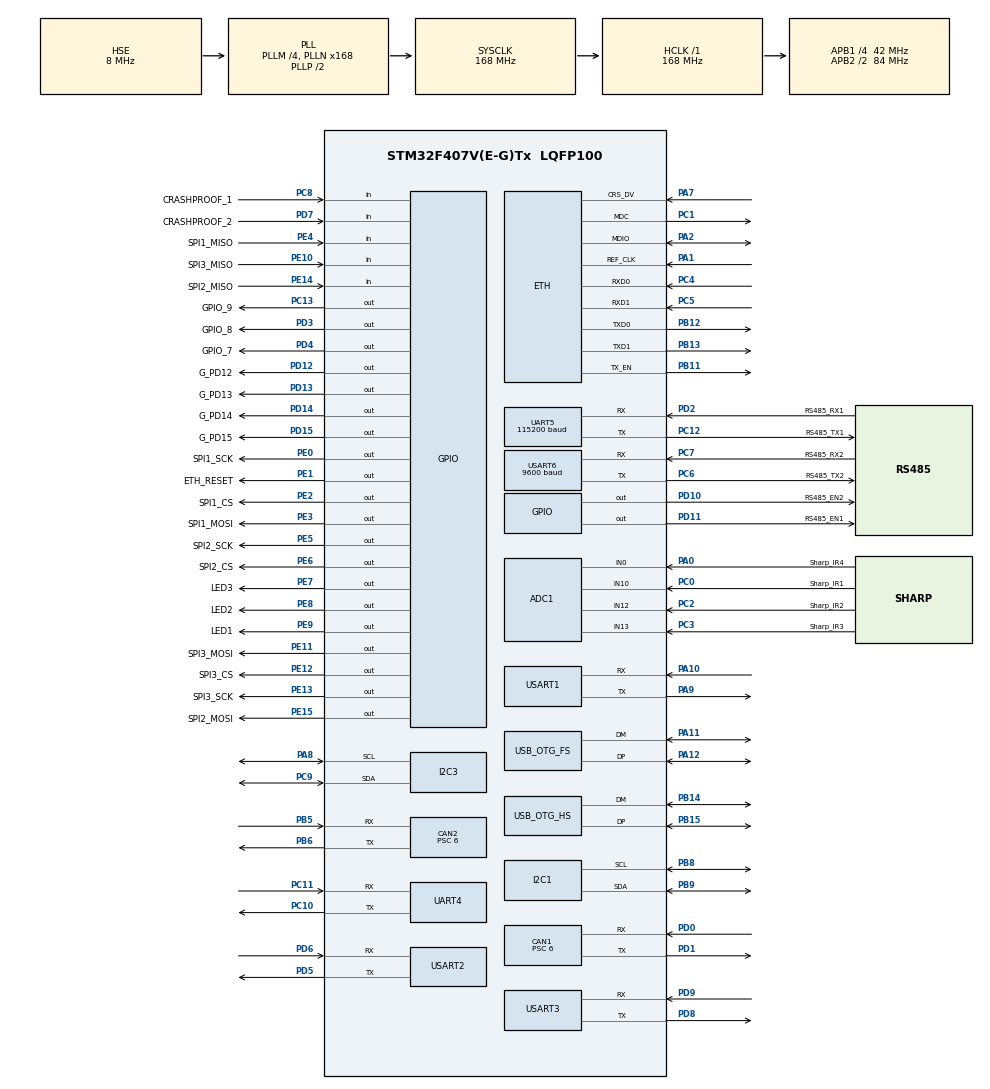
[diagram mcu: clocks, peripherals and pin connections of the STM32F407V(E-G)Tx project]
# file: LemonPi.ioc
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ADC1.Channel-0\#ChannelRegularConversion=ADC_CHANNEL_10
ADC1.Channel-1\#ChannelRegularConversion=ADC_CHANNEL_12
ADC1.Channel-2\#ChannelRegularConversion=ADC_CHANNEL_13
ADC1.Channel-3\#ChannelRegularConversion=ADC_CHANNEL_0
ADC1.ClockPrescaler=ADC_CLOCK_SYNC_PCLK_DIV8
ADC1.ContinuousConvMode=ENABLE
ADC1.DMAContinuousRequests=ENABLE
ADC1.InjNumberOfConversion=0
ADC1.NbrOfConversion=4
ADC1.NbrOfConversionFlag=1
ADC1.Rank-0\#ChannelRegularConversion=1
ADC1.Rank-1\#ChannelRegularConversion=2
ADC1.Rank-2\#ChannelRegularConversion=3
ADC1.Rank-3\#ChannelRegularConversion=4
ADC1.SamplingTime-0\#ChannelRegularConversion=ADC_SAMPLETIME_84CYCLES
ADC1.SamplingTime-1\#ChannelRegularConversion=ADC_SAMPLETIME_84CYCLES
ADC1.SamplingTime-2\#ChannelRegularConversion=ADC_SAMPLETIME_84CYCLES
ADC1.SamplingTime-3\#ChannelRegularConversion=ADC_SAMPLETIME_84CYCLES
ADC1.master=1
CAN1.BS1=CAN_BS1_5TQ
CAN1.CalculateBaudRate=1000000
CAN1.CalculateTimeBit=1000
CAN1.CalculateTimeQuantum=142.85714285714286
CAN1.Prescaler=6
CAN2.BS1=CAN_BS1_5TQ
CAN2.CalculateBaudRate=1000000
CAN2.CalculateTimeBit=1000
CAN2.CalculateTimeQuantum=142.85714285714286
CAN2.Prescaler=6
Dma.ADC1.2.Direction=DMA_PERIPH_TO_MEMORY
Dma.ADC1.2.FIFOMode=DMA_FIFOMODE_DISABLE
Dma.ADC1.2.Instance=DMA2_Stream0
Dma.ADC1.2.MemDataAlignment=DMA_MDATAALIGN_HALFWORD
Dma.ADC1.2.MemInc=DMA_MINC_ENABLE
Dma.ADC1.2.Mode=DMA_CIRCULAR
Dma.ADC1.2.PeriphDataAlignment=DMA_PDATAALIGN_HALFWORD
Dma.ADC1.2.PeriphInc=DMA_PINC_DISABLE
Dma.ADC1.2.Priority=DMA_PRIORITY_HIGH
Dma.Request0=USART1_RX
Dma.Request1=USART1_TX
Dma.Request2=ADC1
Dma.USART1_RX.0.Direction=DMA_PERIPH_TO_MEMORY
Dma.USART1_RX.0.FIFOMode=DMA_FIFOMODE_DISABLE
Dma.USART1_RX.0.Instance=DMA2_Stream2
Dma.USART1_RX.0.MemDataAlignment=DMA_MDATAALIGN_HALFWORD
Dma.USART1_RX.0.MemInc=DMA_MINC_ENABLE
Dma.USART1_RX.0.Mode=DMA_NORMAL
Dma.USART1_RX.0.PeriphDataAlignment=DMA_PDATAALIGN_HALFWORD
Dma.USART1_RX.0.PeriphInc=DMA_PINC_DISABLE
Dma.USART1_RX.0.Priority=DMA_PRIORITY_MEDIUM
Dma.USART1_TX.1.Direction=DMA_MEMORY_TO_PERIPH
Dma.USART1_TX.1.FIFOMode=DMA_FIFOMODE_DISABLE
Dma.USART1_TX.1.Instance=DMA2_Stream7
Dma.USART1_TX.1.MemDataAlignment=DMA_MDATAALIGN_WORD
Dma.USART1_TX.1.MemInc=DMA_MINC_ENABLE
Dma.USART1_TX.1.Mode=DMA_NORMAL
Dma.USART1_TX.1.PeriphDataAlignment=DMA_PDATAALIGN_WORD
Dma.USART1_TX.1.PeriphInc=DMA_PINC_DISABLE
Dma.USART1_TX.1.Priority=DMA_PRIORITY_LOW
ETH.MediaInterface=HAL_ETH_RMII_MODE
I2C1.OwnAddress=15
LWIP.BSP.number=1
LWIP.CHECKSUM_BY_HARDWARE=1
LWIP.DHCP_DEBUG=LWIP_DBG_ON
LWIP.GATEWAY_ADDRESS=192.168.001.001
LWIP.IP_ADDRESS=192.168.001.201
LWIP.IP_REASS_DEBUG=LWIP_DBG_ON
LWIP.LWIP_DHCP=0
LWIP.LWIP_DNS=0
LWIP.LWIP_NETIF_EXT_STATUS_CALLBACK=1
LWIP.LWIP_NETIF_STATUS_CALLBACK=1
LWIP.NETMASK_ADDRESS=255.255.255.000
LWIP.Version=v2.1.2_Cube
LWIP0.BSP.STBoard=false
LWIP0.BSP.api=BSP_COMPONENT_DRIVER
LWIP0.BSP.component=LAN8742
LWIP0.BSP.instance=LAN8742
LWIP0.BSP.name=Driver_PHY
LWIP0.BSP.semaphore=S_LAN8742
LWIP0.BSP.solution=LAN8742
Mcu.Family=STM32F4
Mcu.Name=STM32F407V(E-G)Tx
Mcu.Package=LQFP100
NVIC.CAN1_RX0_IRQn=true\:0\:0\:false\:false\:true\:true\:true\:true
NVIC.CAN2_RX0_IRQn=true\:0\:0\:false\:false\:true\:true\:true\:true
NVIC.DMA2_Stream0_IRQn=true\:0\:0\:false\:false\:true\:false\:true\:true
NVIC.DMA2_Stream2_IRQn=true\:0\:0\:false\:false\:true\:false\:true\:true
NVIC.DMA2_Stream7_IRQn=true\:0\:0\:false\:false\:true\:false\:true\:true
NVIC.OTG_FS_IRQn=true\:0\:0\:false\:false\:true\:false\:true\:true
NVIC.OTG_HS_IRQn=true\:0\:0\:false\:false\:true\:false\:true\:true
NVIC.PriorityGroup=NVIC_PRIORITYGROUP_4
NVIC.TIM2_IRQn=true\:3\:0\:true\:false\:true\:true\:true\:true
NVIC.UART4_IRQn=true\:0\:0\:false\:false\:true\:true\:true\:true
NVIC.UART5_IRQn=true\:0\:0\:false\:false\:true\:true\:true\:true
NVIC.USART1_IRQn=true\:0\:0\:false\:false\:true\:true\:true\:true
NVIC.USART2_IRQn=true\:2\:0\:true\:false\:true\:true\:true\:true
NVIC.USART3_IRQn=true\:0\:0\:false\:false\:true\:true\:true\:true
NVIC.USART6_IRQn=true\:0\:0\:true\:false\:true\:true\:true\:true
PA0-WKUP.GPIO_Label=Sharp_IR4
PA0-WKUP.Signal=ADCx_IN0
PA1.GPIO_Speed=GPIO_SPEED_FREQ_HIGH
PA1.Mode=RMII
PA1.Signal=ETH_REF_CLK
PA10.Mode=Asynchronous
PA10.Signal=USART1_RX
PA11.Mode=Device_Only
PA11.Signal=USB_OTG_FS_DM
PA12.Mode=Device_Only
PA12.Signal=USB_OTG_FS_DP
PA13.Mode=JTAG_5_pins
PA13.Signal=SYS_JTMS-SWDIO
PA14.Mode=JTAG_5_pins
PA14.Signal=SYS_JTCK-SWCLK
PA15.Mode=JTAG_5_pins
PA15.Signal=SYS_JTDI
PA2.GPIO_Speed=GPIO_SPEED_FREQ_HIGH
PA2.Mode=RMII
PA2.Signal=ETH_MDIO
PA7.GPIO_Speed=GPIO_SPEED_FREQ_HIGH
PA7.Mode=RMII
PA7.Signal=ETH_CRS_DV
PA8.GPIO_Pu=GPIO_PULLUP
PA8.Mode=I2C
PA8.Signal=I2C3_SCL
PA9.Mode=Asynchronous
PA9.Signal=USART1_TX
PB11.GPIO_Speed=GPIO_SPEED_FREQ_HIGH
PB11.Mode=RMII
PB11.Signal=ETH_TX_EN
PB12.GPIO_Speed=GPIO_SPEED_FREQ_HIGH
PB12.Mode=RMII
PB12.Signal=ETH_TXD0
PB13.GPIO_Speed=GPIO_SPEED_FREQ_HIGH
PB13.Mode=RMII
PB13.Signal=ETH_TXD1
PB14.Mode=Device_Only_FS
PB14.Signal=USB_OTG_HS_DM
PB15.Mode=Device_Only_FS
PB15.Signal=USB_OTG_HS_DP
PB2.Signal=EVENTOUT
PB3.Mode=JTAG_5_pins
PB3.Signal=SYS_JTDO-SWO
PB4.Mode=JTAG_5_pins
PB4.Signal=SYS_JTRST
PB5.Mode=CAN_Activate
PB5.Signal=CAN2_RX
PB6.Mode=CAN_Activate
PB6.Signal=CAN2_TX
PB8.GPIO_Pu=GPIO_PULLUP
PB8.Mode=I2C
PB8.Signal=I2C1_SCL
PB9.GPIO_Pu=GPIO_PULLUP
PB9.Mode=I2C
PB9.Signal=I2C1_SDA
PC0.GPIO_Label=Sharp_IR1
PC0.Signal=ADCx_IN10
PC1.GPIO_Speed=GPIO_SPEED_FREQ_HIGH
PC1.Mode=RMII
PC1.Signal=ETH_MDC
PC10.Mode=Asynchronous
PC10.Signal=UART4_TX
PC11.Mode=Asynchronous
PC11.Signal=UART4_RX
PC12.GPIO_Label=RS485_TX1
PC12.GPIO_Speed=GPIO_SPEED_FREQ_MEDIUM
PC12.Mode=Asynchronous
PC12.Signal=UART5_TX
PC13-ANTI_TAMP.GPIO_Label=GPIO_9
PC13-ANTI_TAMP.GPIO_ModeDefaultOutputPP=GPIO_MODE_OUTPUT_PP
PC13-ANTI_TAMP.GPIO_PuPd=GPIO_PULLUP
PC13-ANTI_TAMP.GPIO_Speed=GPIO_SPEED_FREQ_LOW
PC13-ANTI_TAMP.PinState=GPIO_PIN_SET
PC13-ANTI_TAMP.Signal=GPIO_Output
PC14-OSC32_IN.Mode=LSE-External-Oscillator
PC14-OSC32_IN.Signal=RCC_OSC32_IN
PC15-OSC32_OUT.Mode=LSE-External-Oscillator
PC15-OSC32_OUT.Signal=RCC_OSC32_OUT
PC2.GPIO_Label=Sharp_IR2
PC2.Signal=ADCx_IN12
PC3.GPIO_Label=Sharp_IR3
PC3.Signal=ADCx_IN13
PC4.GPIO_Speed=GPIO_SPEED_FREQ_HIGH
PC4.Mode=RMII
PC4.Signal=ETH_RXD0
PC5.GPIO_Speed=GPIO_SPEED_FREQ_HIGH
PC5.Mode=RMII
PC5.Signal=ETH_RXD1
PC6.GPIO_Label=RS485_TX2
PC6.GPIO_Speed=GPIO_SPEED_FREQ_MEDIUM
PC6.Mode=Asynchronous
PC6.Signal=USART6_TX
PC7.GPIO_Label=RS485_RX2
PC7.GPIO_Speed=GPIO_SPEED_FREQ_MEDIUM
PC7.Mode=Asynchronous
PC7.Signal=USART6_RX
PC8.GPIO_Label=CRASHPROOF_1
PC8.GPIO_PuPd=GPIO_PULLDOWN
PC8.Signal=GPIO_Input
PC9.GPIO_Pu=GPIO_PULLUP
PC9.Mode=I2C
PC9.Signal=I2C3_SDA
PD0.Mode=CAN_Activate
PD0.Signal=CAN1_RX
PD1.Mode=CAN_Activate
PD1.Signal=CAN1_TX
PD10.GPIO_Label=RS485_EN2
PD10.GPIO_PuPd=GPIO_PULLDOWN
PD10.GPIO_Speed=GPIO_SPEED_FREQ_VERY_HIGH
PD10.PinState=GPIO_PIN_RESET
PD10.Signal=GPIO_Output
PD11.GPIO_Label=RS485_EN1
PD11.GPIO_PuPd=GPIO_PULLDOWN
PD11.GPIO_Speed=GPIO_SPEED_FREQ_VERY_HIGH
PD11.PinState=GPIO_PIN_RESET
PD11.Signal=GPIO_Output
PD12.GPIO_Label=G_PD12
PD12.GPIO_PuPd=GPIO_PULLDOWN
PD12.GPIO_Speed=GPIO_SPEED_FREQ_HIGH
PD12.Signal=GPIO_Output
PD13.GPIO_Label=G_PD13
PD13.GPIO_ModeDefaultOutputPP=GPIO_MODE_OUTPUT_PP
PD13.GPIO_PuPd=GPIO_PULLDOWN
PD13.GPIO_Speed=GPIO_SPEED_FREQ_HIGH
PD13.Signal=GPIO_Output
PD14.GPIO_Label=G_PD14
PD14.GPIO_PuPd=GPIO_PULLDOWN
PD14.GPIO_Speed=GPIO_SPEED_FREQ_HIGH
PD14.Signal=GPIO_Output
PD15.GPIO_Label=G_PD15
PD15.GPIO_PuPd=GPIO_PULLDOWN
PD15.GPIO_Speed=GPIO_SPEED_FREQ_HIGH
PD15.Signal=GPIO_Output
PD2.GPIO_Label=RS485_RX1
PD2.GPIO_Speed=GPIO_SPEED_FREQ_MEDIUM
PD2.Mode=Asynchronous
PD2.Signal=UART5_RX
PD3.GPIO_Label=GPIO_8
PD3.GPIO_PuPd=GPIO_PULLUP
PD3.GPIO_Speed=GPIO_SPEED_FREQ_HIGH
PD3.PinState=GPIO_PIN_SET
PD3.Signal=GPIO_Output
PD4.GPIO_Label=GPIO_7
PD4.GPIO_PuPd=GPIO_PULLUP
PD4.GPIO_Speed=GPIO_SPEED_FREQ_HIGH
PD4.PinState=GPIO_PIN_SET
PD4.Signal=GPIO_Output
PD5.GPIO_PuPd=GPIO_PULLUP
PD5.Mode=Asynchronous
PD5.Signal=USART2_TX
PD6.GPIO_PuPd=GPIO_PULLUP
PD6.Mode=Asynchronous
PD6.Signal=USART2_RX
PD7.GPIO_Label=CRASHPROOF_2
PD7.GPIO_PuPd=GPIO_PULLDOWN
PD7.Signal=GPIO_Input
PD8.Mode=Asynchronous
PD8.Signal=USART3_TX
PD9.Mode=Asynchronous
PD9.Signal=USART3_RX
PE0.GPIO_Label=SPI1_SCK
PE0.GPIO_PuPd=GPIO_PULLDOWN
PE0.GPIO_Speed=GPIO_SPEED_FREQ_HIGH
PE0.PinState=GPIO_PIN_RESET
PE0.Signal=GPIO_Output
PE1.GPIO_Label=ETH_RESET
PE1.GPIO_PuPd=GPIO_PULLDOWN
PE1.GPIO_Speed=GPIO_SPEED_FREQ_MEDIUM
PE1.Signal=GPIO_Output
PE10.GPIO_Label=SPI3_MISO
PE10.GPIO_PuPd=GPIO_PULLDOWN
PE10.Signal=GPIO_Input
PE11.GPIO_Label=SPI3_MOSI
PE11.GPIO_PuPd=GPIO_PULLUP
PE11.GPIO_Speed=GPIO_SPEED_FREQ_HIGH
PE11.PinState=GPIO_PIN_SET
PE11.Signal=GPIO_Output
PE12.GPIO_Label=SPI3_CS
PE12.GPIO_PuPd=GPIO_PULLDOWN
PE12.GPIO_Speed=GPIO_SPEED_FREQ_HIGH
PE12.PinState=GPIO_PIN_RESET
PE12.Signal=GPIO_Output
PE13.GPIO_Label=SPI3_SCK
PE13.GPIO_Speed=GPIO_SPEED_FREQ_HIGH
PE13.Signal=GPIO_Output
PE14.GPIO_Label=SPI2_MISO
PE14.GPIO_PuPd=GPIO_NOPULL
PE14.Signal=GPIO_Input
PE15.GPIO_Label=SPI2_MOSI
PE15.GPIO_Speed=GPIO_SPEED_FREQ_HIGH
PE15.Signal=GPIO_Output
PE2.GPIO_Label=SPI1_CS
PE2.GPIO_PuPd=GPIO_PULLUP
PE2.GPIO_Speed=GPIO_SPEED_FREQ_HIGH
PE2.PinState=GPIO_PIN_SET
PE2.Signal=GPIO_Output
PE3.GPIO_Label=SPI1_MOSI
PE3.GPIO_PuPd=GPIO_NOPULL
PE3.GPIO_Speed=GPIO_SPEED_FREQ_HIGH
PE3.PinState=GPIO_PIN_SET
PE3.Signal=GPIO_Output
PE4.GPIO_Label=SPI1_MISO
PE4.GPIO_PuPd=GPIO_PULLUP
PE4.Signal=GPIO_Input
PE5.GPIO_Label=SPI2_SCK
PE5.GPIO_PuPd=GPIO_PULLUP
PE5.GPIO_Speed=GPIO_SPEED_FREQ_HIGH
PE5.PinState=GPIO_PIN_SET
PE5.Signal=GPIO_Output
PE6.GPIO_Label=SPI2_CS
PE6.GPIO_PuPd=GPIO_PULLDOWN
PE6.GPIO_Speed=GPIO_SPEED_FREQ_HIGH
PE6.Signal=GPIO_Output
PE7.GPIO_Label=LED3
PE7.GPIO_PuPd=GPIO_PULLUP
PE7.GPIO_Speed=GPIO_SPEED_FREQ_HIGH
PE7.PinState=GPIO_PIN_SET
PE7.Signal=GPIO_Output
PE8.GPIO_Label=LED2
PE8.GPIO_ModeDefaultOutputPP=GPIO_MODE_OUTPUT_PP
PE8.GPIO_PuPd=GPIO_PULLUP
PE8.GPIO_Speed=GPIO_SPEED_FREQ_HIGH
PE8.PinState=GPIO_PIN_SET
PE8.Signal=GPIO_Output
PE9.GPIO_Label=LED1
PE9.GPIO_ModeDefaultOutputPP=GPIO_MODE_OUTPUT_PP
PE9.GPIO_PuPd=GPIO_PULLUP
PE9.GPIO_Speed=GPIO_SPEED_FREQ_HIGH
PE9.PinState=GPIO_PIN_SET
PE9.Signal=GPIO_Output
PH0-OSC_IN.Mode=HSE-External-Oscillator
PH0-OSC_IN.Signal=RCC_OSC_IN
PH1-OSC_OUT.Mode=HSE-External-Oscillator
PH1-OSC_OUT.Signal=RCC_OSC_OUT
ProjectManager.HeapSize=0x200
ProjectManager.StackSize=0x400
ProjectManager.TargetToolchain=STM32CubeIDE
RCC.48MHZClocksFreq_Value=48000000
RCC.AHBFreq_Value=168000000
RCC.APB1CLKDivider=RCC_HCLK_DIV4
RCC.APB1Freq_Value=42000000
RCC.APB1TimFreq_Value=84000000
RCC.APB2CLKDivider=RCC_HCLK_DIV2
RCC.APB2Freq_Value=84000000
RCC.APB2TimFreq_Value=168000000
RCC.CortexFreq_Value=168000000
RCC.HCLKFreq_Value=168000000
RCC.HSE_VALUE=8000000
RCC.HSI_VALUE=16000000
RCC.PLLM=4
RCC.PLLN=168
RCC.PLLQ=7
RCC.RCC_RTC_Clock_Source=RCC_RTCCLKSOURCE_LSE
RCC.RCC_RTC_Clock_SourceVirtual=RCC_RTCCLKSOURCE_LSE
RCC.SYSCLKFreq_VALUE=168000000
RCC.SYSCLKSource=RCC_SYSCLKSOURCE_PLLCLK
RCC.VCOOutputFreq_Value=336000000
SH.ADCx_IN0.0=ADC1_IN0,IN0
SH.ADCx_IN10.0=ADC1_IN10,IN10
SH.ADCx_IN12.0=ADC1_IN12,IN12
SH.ADCx_IN13.0=ADC1_IN13,IN13
TIM2.AutoReloadPreload=TIM_AUTORELOAD_PRELOAD_ENABLE
TIM2.Period=1000-1
TIM2.Prescaler=4200-1
UART4.VirtualMode=Asynchronous
UART5.BaudRate=115200
UART5.VirtualMode=Asynchronous
USART1.VirtualMode=VM_ASYNC
USART2.VirtualMode=VM_ASYNC
USART3.VirtualMode=VM_ASYNC
USART6.BaudRate=9600
USART6.VirtualMode=VM_ASYNC
USB_DEVICE.CLASS_NAME_FS=CDC
USB_DEVICE.CLASS_NAME_HS=CDC
USB_DEVICE.VirtualMode-CDC_FS=Cdc
USB_DEVICE.VirtualMode-CDC_HS=Cdc
USB_DEVICE.VirtualModeFS=Cdc_FS
USB_DEVICE.VirtualModeHS=Cdc_HS
USB_OTG_FS.Sof_enable=ENABLE
USB_OTG_FS.VirtualMode=Device_Only
USB_OTG_HS.VirtualMode-Device_Only_FS=Device_Only_FS
VP_LWIP_VS_Enabled.Mode=Enabled
VP_RTC_VS_RTC_Activate.Mode=RTC_Enabled
VP_RTC_VS_RTC_Calendar.Mode=RTC_Calendar
VP_TIM2_VS_ClockSourceINT.Mode=Internal
VP_USB_DEVICE_VS_USB_DEVICE_CDC_FS.Mode=CDC_FS
VP_USB_DEVICE_VS_USB_DEVICE_CDC_HS.Mode=CDC_HS
board=custom

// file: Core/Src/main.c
/* USER CODE BEGIN Header */
/**
  ******************************************************************************
  * @file           : main.c
  * @brief          : Main program body
  ******************************************************************************
  * @attention
  *
  * Copyright (c) 2024 STMicroelectronics.
  * All rights reserved.
  *
  * This software is licensed under terms that can be found in the LICENSE file
  * in the root directory of this software component.
  * If no LICENSE file comes with this software, it is provided AS-IS.
  *
  ******************************************************************************
  */
/* USER CODE END Header */
#include "main.h"
#include "adc.h"
#include "can.h"
#include "dma.h"
#include "i2c.h"
#include "lwip.h"
#include "rtc.h"
#include "tim.h"
#include "usart.h"
#include "usb_device.h"
#include "gpio.h"

/* USER CODE BEGIN Includes */
//#include "led.h"
//extern void Test_main();
/* USER CODE END Includes */

void SystemClock_Config(void);

/* USER CODE BEGIN 0 */
uint16_t ad_buf[6] = {0};
/* USER CODE END 0 */

int main(void)
{

  /* MCU Configuration--------------------------------------------------------*/

  /* Reset of all peripherals, Initializes the Flash interface and the Systick. */
  HAL_Init();

  /* Configure the system clock */
  SystemClock_Config();

  /* Initialize all configured peripherals */
  MX_GPIO_Init();
  MX_DMA_Init();
  MX_ADC1_Init();
  MX_CAN1_Init();
  MX_CAN2_Init();
  MX_I2C1_Init();
  MX_I2C3_Init();
  MX_UART4_Init();
  MX_UART5_Init();
  MX_USART1_UART_Init();
  MX_USART2_UART_Init();
  MX_USART3_UART_Init();
  MX_LWIP_Init();
  MX_TIM2_Init();
  MX_USART6_UART_Init();
  MX_USB_DEVICE_Init();
  MX_RTC_Init();
  /* USER CODE BEGIN 2 */
  HAL_ADC_Start_DMA(&hadc1, (uint32_t*)&ad_buf, 4);

//  HAL_GPIO_WritePin(G_PD12_GPIO_Port, G_PD12_Pin, GPIO_PIN_SET);
//  HAL_GPIO_WritePin(G_PD13_GPIO_Port, G_PD13_Pin, GPIO_PIN_SET);
//  HAL_GPIO_WritePin(G_PD14_GPIO_Port, G_PD14_Pin, GPIO_PIN_SET);
//  HAL_GPIO_WritePin(G_PD15_GPIO_Port, G_PD15_Pin, GPIO_PIN_SET);
  /* USER CODE END 2 */

  /* Infinite loop */
  /* USER CODE BEGIN WHILE */
  while (1)
  {
	  MX_LWIP_Process();
	  HAL_Delay(50);
	  //LED1_TOGGLE();
    /* USER CODE END WHILE */

  }
}

void SystemClock_Config(void)
{
  RCC_OscInitTypeDef RCC_OscInitStruct = {0};
  RCC_ClkInitTypeDef RCC_ClkInitStruct = {0};

  /** Configure the main internal regulator output voltage
  */
  __HAL_RCC_PWR_CLK_ENABLE();
  __HAL_PWR_VOLTAGESCALING_CONFIG(PWR_REGULATOR_VOLTAGE_SCALE1);

  /** Initializes the RCC Oscillators according to the specified parameters
  * in the RCC_OscInitTypeDef structure.
  */
  RCC_OscInitStruct.OscillatorType = RCC_OSCILLATORTYPE_HSE|RCC_OSCILLATORTYPE_LSE;
  RCC_OscInitStruct.HSEState = RCC_HSE_ON;
  RCC_OscInitStruct.LSEState = RCC_LSE_ON;
  RCC_OscInitStruct.PLL.PLLState = RCC_PLL_ON;
  RCC_OscInitStruct.PLL.PLLSource = RCC_PLLSOURCE_HSE;
  RCC_OscInitStruct.PLL.PLLM = 4;
  RCC_OscInitStruct.PLL.PLLN = 168;
  RCC_OscInitStruct.PLL.PLLP = RCC_PLLP_DIV2;
  RCC_OscInitStruct.PLL.PLLQ = 7;
  if (HAL_RCC_OscConfig(&RCC_OscInitStruct) != HAL_OK)
  {
    Error_Handler();
  }

  /** Initializes the CPU, AHB and APB buses clocks
  */
  RCC_ClkInitStruct.ClockType = RCC_CLOCKTYPE_HCLK|RCC_CLOCKTYPE_SYSCLK
                              |RCC_CLOCKTYPE_PCLK1|RCC_CLOCKTYPE_PCLK2;
  RCC_ClkInitStruct.SYSCLKSource = RCC_SYSCLKSOURCE_PLLCLK;
  RCC_ClkInitStruct.AHBCLKDivider = RCC_SYSCLK_DIV1;
  RCC_ClkInitStruct.APB1CLKDivider = RCC_HCLK_DIV4;
  RCC_ClkInitStruct.APB2CLKDivider = RCC_HCLK_DIV2;

  if (HAL_RCC_ClockConfig(&RCC_ClkInitStruct, FLASH_LATENCY_5) != HAL_OK)
  {
    Error_Handler();
  }
}

void Error_Handler(void)
{
  __disable_irq();
  while (1)
  {
  }
}
